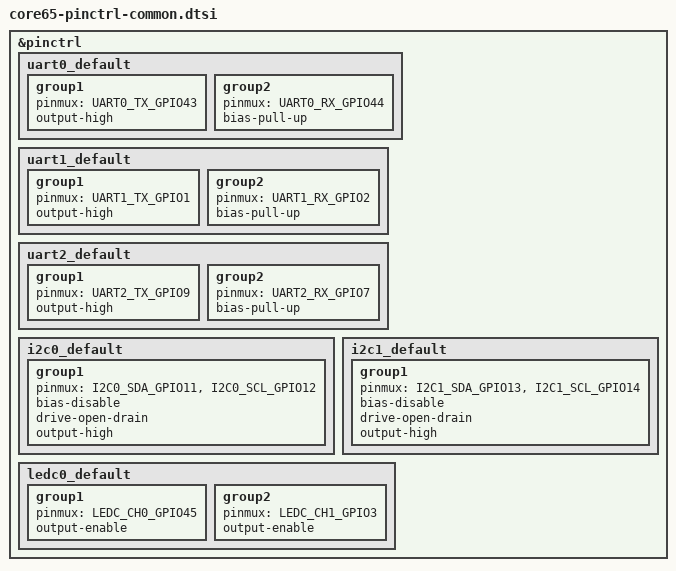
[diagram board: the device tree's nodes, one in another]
/*
 * Copyright (c) 2024 Espressif Systems (Shanghai) Co., Ltd.
 * Copyright (c) 2026 Auxspace e.V.
 *
 * SPDX-License-Identifier: Apache-2.0
 *
 * Pin assignments for AUX-Core-6501.
 *
 * The board has no I2S or SPI peripherals: GPIO4-7 and GPIO40-42 are taken
 * by the native SDHC slot and the bottom connector's UART, so no I2S or SPI
 * groups are defined here.  Adding one would collide with the SD card.
 */

#include <zephyr/dt-bindings/pinctrl/esp-pinctrl-common.h>
#include <dt-bindings/pinctrl/esp32s3-pinctrl.h>
#include <zephyr/dt-bindings/pinctrl/esp32s3-gpio-sigmap.h>

&pinctrl {
	/* Debug header J5 (GND / VBus / TX / RX) */
	uart0_default: uart0_default {
		group1 {
			pinmux = <UART0_TX_GPIO43>;
			output-high;
		};

		group2 {
			pinmux = <UART0_RX_GPIO44>;
			bias-pull-up;
		};
	};

	/* Top AUX-Stack data connector J1 (UART_TX_top / UART_RX_top) */
	uart1_default: uart1_default {
		group1 {
			pinmux = <UART1_TX_GPIO1>;
			output-high;
		};

		group2 {
			pinmux = <UART1_RX_GPIO2>;
			bias-pull-up;
		};
	};

	/* Bottom AUX-Stack data connector J2 (UART_TX_bot / UART_RX_bot) */
	uart2_default: uart2_default {
		group1 {
			pinmux = <UART2_TX_GPIO9>;
			output-high;
		};

		group2 {
			pinmux = <UART2_RX_GPIO7>;
			bias-pull-up;
		};
	};

	/* On-board sensor bus. */
	i2c0_default: i2c0_default {
		group1 {
			pinmux = <I2C0_SDA_GPIO11>,
				 <I2C0_SCL_GPIO12>;
			bias-disable;
			drive-open-drain;
			output-high;
		};
	};

	/* AUX-Stack data connector bus, shared by J1 and J2 through the R5/R7
	 * links.
	 */
	i2c1_default: i2c1_default {
		group1 {
			pinmux = <I2C1_SDA_GPIO13>,
				 <I2C1_SCL_GPIO14>;
			bias-disable;
			drive-open-drain;
			output-high;
		};
	};

	/* Channel 0 drives the buzzer, channel 1 the STATE LED. */
	ledc0_default: ledc0_default {
		group1 {
			pinmux = <LEDC_CH0_GPIO45>;
			output-enable;
		};
		group2 {
			pinmux = <LEDC_CH1_GPIO3>;
			output-enable;
		};
	};
};
